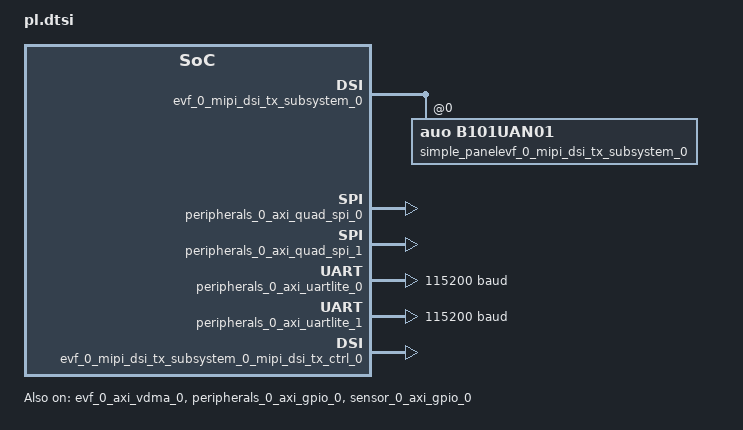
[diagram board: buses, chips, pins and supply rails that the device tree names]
/ {
	amba_pl: amba_pl {
		ranges;
		compatible = "simple-bus";
		#address-cells = <1>;
		#size-cells = <1>;
		evf_0_axi_vdma_0: axi_vdma@43000000 {
			xlnx,enable-debug-info-9 = <0x0>;
			xlnx,c-enable-mm2s-param-updt = <0>;
			xlnx,c-enable-s2mm-delay-counter = <1>;
			xlnx,dlytmr-resolution = <125>;
			xlnx,rable = <0>;
			xlnx,ip-name = "axi_vdma";
			xlnx,s2mm-genlock-num-masters = <1>;
			reg = <0x43000000 0x10000>;
			xlnx,use-mm2s-fsync = <0>;
			xlnx,s2mm-linebuffer-thresh = <4>;
			xlnx,c-use-s2mm-fsync = <2>;
			xlnx,c-enable-mm2s-buf-empty = <0>;
			xlnx,c-enable-s2mm-frm-counter = <1>;
			xlnx,c-enable-mm2s-delay-counter = <1>;
			xlnx,c-dlytmr-resolution = <125>;
			xlnx,c-enable-s2mm-buf-full = <0>;
			xlnx,dynamic-resolution = <1>;
			interrupt-names = "mm2s_introut";
			xlnx,s2mm-sof-enable = <0x1>;
			xlnx,mm2s-genlock-num-masters = <1>;
			xlnx,c-s2mm-genlock-num-masters = <1>;
			xlnx,c-enable-s2mm-fsync-out = <0>;
			xlnx,mm2s-linebuffer-thresh = <4>;
			xlnx,c-use-mm2s-fsync = <0>;
			xlnx,c-s2mm-linebuffer-thresh = <4>;
			xlnx,c-enable-mm2s-frm-counter = <1>;
			compatible = "xlnx,axi-vdma-6.3" , "xlnx,axi-vdma-1.00.a";
			xlnx,c-m-axis-mm2s-tdata-width = <96>;
			xlnx,c-enable-all = <0>;
			interrupt-parent = <&intc>;
			xlnx,s2mm-max-burst-length = <8>;
			xlnx,c-dynamic-resolution = <1>;
			xlnx,c-enable-s2mm-rst-out = <0>;
			xlnx,mm2s-sof-enable = <1>;
			xlnx,include-s2mm-dre = <0x0>;
			xlnx,c-s2mm-sof-enable = <1>;
			xlnx,c-enable-mm2s-fsync-out = <0>;
			xlnx,c-mm2s-genlock-num-masters = <1>;
			xlnx,c-mm2s-linebuffer-thresh = <4>;
			xlnx,c-enable-tstvec = <0>;
			xlnx,mm2s-max-burst-length = <256>;
			xlnx,c-s2mm-max-burst-length = <8>;
			status = "okay";
			xlnx,c-enable-mm2s-rst-out = <0>;
			xlnx,include-mm2s-dre = <0x0>;
			xlnx,c-include-s2mm-dre = <0>;
			xlnx,c-mm2s-sof-enable = <1>;
			xlnx,name = "evf_0_axi_vdma_0";
			xlnx,c-enable-s2mm-frmstr-reg = <0>;
			interrupts = < 0 33 4 >;
			xlnx,c-include-sg = <0>;
			xlnx,flush-on-fsync = <0x1>;
			xlnx,c-m-axi-s2mm-data-width = <64>;
			xlnx,c-enable-s2mm-sts-reg = <0>;
			xlnx,include-s2mm-sf = <1>;
			xlnx,c-mm2s-max-burst-length = <256>;
			xlnx,s2mm-linebuffer-depth = <0x200>;
			xlnx,include-s2mm = <0x0>;
			xlnx,c-include-mm2s-dre = <0>;
			clocks = <&clkc 15>, <&clkc 15>, <&clkc 15>;
			xlnx,c-enable-mm2s-frmstr-reg = <0>;
			xlnx,enable-debug-info-10 = <0>;
			xlnx,addrwidth = <0x20>;
			xlnx,enable-debug-info-11 = <0>;
			xlnx,enable-debug-info-12 = <0>;
			xlnx,edk-iptype = "PERIPHERAL";
			xlnx,c-flush-on-fsync = <1>;
			xlnx,c-m-axi-mm2s-data-width = <128>;
			xlnx,use-fsync = <1>;
			xlnx,s2mm-genlock-repeat-en = <1>;
			xlnx,enable-vert-flip = <0x0>;
			xlnx,enable-debug-info-13 = <0x0>;
			xlnx,include-mm2s-sf = <0>;
			xlnx,include-internal-genlock = <0x1>;
			xlnx,enable-debug-info-14 = <0x1>;
			xlnx,c-include-s2mm-sf = <1>;
			clock-names = "m_axi_mm2s_aclk" , "m_axis_mm2s_aclk" , "s_axi_lite_aclk";
			xlnx,enable-debug-info-15 = <0x1>;
			xlnx,mm2s-linebuffer-depth = <0x200>;
			xlnx,include-mm2s = <0x1>;
			xlnx,c-single-interface = <0>;
			xlnx,c-s2mm-linebuffer-depth = <512>;
			xlnx,c-addr-width = <32>;
			xlnx,c-include-s2mm = <0>;
			xlnx,s2mm-genlock-mode = <0x0>;
			xlnx,c-s-axis-s2mm-tdata-width = <32>;
			xlnx,flush-fsync = <0x1>;
			xlnx,select-xpm = <0>;
			xlnx,s2mm-data-width = <0x40>;
			xlnx,num-fstores = <0x1>;
			xlnx,enable-vidparam-reads = <0x1>;
			xlnx,mm2s-genlock-repeat-en = <0>;
			xlnx,c-use-fsync = <1>;
			xlnx,c-s2mm-genlock-repeat-en = <1>;
			xlnx,c-enable-vert-flip = <0>;
			xlnx,prmry-is-aclk-async = <0>;
			xlnx,c-include-internal-genlock = <1>;
			xlnx,c-include-mm2s-sf = <0>;
			xlnx,s2mm-tdata-width = <0x20>;
			xlnx,enable-vidprmtr-reads = <1>;
			xlnx,c-include-mm2s = <1>;
			xlnx,c-mm2s-linebuffer-depth = <512>;
			xlnx,mm2s-genlock-mode = <0x0>;
			xlnx,enable-debug-info-0 = <0>;
			xlnx,enable-debug-all = <0x0>;
			xlnx,c-s2mm-genlock-mode = <0>;
			xlnx,enable-debug-info-1 = <0x0>;
			xlnx,mm2s-data-width = <0x80>;
			xlnx,enable-debug-info-2 = <0>;
			xlnx,c-enable-s2mm-param-updt = <0>;
			xlnx,c-num-fstores = <1>;
			xlnx,enable-debug-info-3 = <0>;
			xlnx,enable-debug-info-4 = <0>;
			xlnx,c-mm2s-genlock-repeat-en = <0>;
			xlnx,enable-debug-info-5 = <0x0>;
			xlnx,c-prmry-is-aclk-async = <0>;
			xlnx,mm2s-tdata-width = <0x60>;
			xlnx,enable-debug-info-6 = <0x1>;
			xlnx,enable-debug-info-7 = <0x1>;
			xlnx,c-enable-vidprmtr-reads = <1>;
			xlnx,use-s2mm-fsync = <2>;
			xlnx,enable-debug-info-8 = <0>;
			xlnx,c-mm2s-genlock-mode = <0>;
			dma-channel@43000000 {
				interrupts = < 0 33 4 >;
				xlnx,datawidth = <0x60>;
				xlnx,device-id = <0x0>;
				compatible = "xlnx,axi-vdma-mm2s-channel";
			};
		};
		evf_0_mipi_dsi_tx_subsystem_0: mipi_dsi_tx_subsystem@43c00000 {
			xlnx,data-lane2-byte = "Same_Byte";
			xlnx,hp-io-bank-name = "64_(HP)";
			xlnx,dphy-lanes = <4>;
			xlnx,dsi-periodic-cntr-width = <32>;
			xlnx,rable = <0>;
			xlnx,ip-name = "mipi_dsi_tx_subsystem";
			reg = <0x43c00000 0x10000>;
			xlnx,dsi-byte-fifo = <2048>;
			xlnx,dsi-periodic-patrn-len = <4096>;
			xlnx,supportlevel = <1>;
			xlnx,clk-lane-io-loc-name = "None";
			xlnx,dsi-data-type = <0>;
			xlnx,include-dcs-cmd-mode;
			xlnx,clk-lane-io-loc = "None";
			interrupt-names = "interrupt";
			xlnx,dphy-hs-timeout = <65541>;
			compatible = "xlnx,mipi-dsi-tx-subsystem-2.3" , "xlnx,dsi";
			xlnx,is-7series;
			xlnx,idly-tap = <1>;
			xlnx,dsi-crc-gen;
			xlnx,dsi-num-lanes = <4>;
			xlnx,cmn-proj-family = <0>;
			interrupt-parent = <&intc>;
			xlnx,data-lane1-io-loc-name = "None";
			xlnx,dsi-init-deskew-patrn-len = <4096>;
			xlnx,data-lane3-io-loc-name = "None";
			xlnx,data-lane1-byte = "Same_Byte";
			xlnx,dphy-esc-timeout = <25600>;
			xlnx,dsi-datatype = "RGB888";
			xlnx,cal-mode = "NONE";
			status = "okay";
			xlnx,data-lane0-io-position = <2>;
			xlnx,data-lane2-io-position = <6>;
			xlnx,name = "evf_0_mipi_dsi_tx_subsystem_0";
			interrupts = < 0 34 4 >;
			xlnx,data-lane3-io-loc = "None";
			xlnx,dphy-linerate = <800>;
			xlnx,dsi-lanes = <4>;
			clocks = <&misc_clk_0>, <&clkc 15>;
			xlnx,mipi-slv-int = <0>;
			xlnx,data-lane2-io-loc = "None";
			xlnx,dsi-pixels-perbeat = <4>;
			xlnx,stretch-line-rate = <3200>;
			xlnx,data-lane3-byte = "Same_Byte";
			xlnx,dphy-esc-clk-period = <20>;
			xlnx,edk-iptype = "PERIPHERAL";
			clock-names = "dphy_clk_200M" , "s_axis_aclk";
			xlnx,ooc-vid-clk = <0x65b710>;
			xlnx,data-lane0-byte = "Same_Byte";
			xlnx,data-lane1-io-loc = "None";
			xlnx,hp-io-bank-selection = <64>;
			xlnx,dsi-pixels = <4>;
			xlnx,dphytx-board-interface = "Custom";
			xlnx,data-lane0-io-loc-name = "None";
			xlnx,dphy-preset = "None";
			xlnx,clk-lane-io-position = <0>;
			xlnx,data-lane0-io-loc = "None";
			xlnx,data-lane2-io-loc-name = "None";
			xlnx,hs-line-rate = <800>;
			xlnx,axis-tdata-width = <96>;
			xlnx,dphy-lpx-period = <50>;
			xlnx,data-lane1-io-position = <4>;
			xlnx,dphy-mode = "MASTER";
			xlnx,dsi-periodic-time = <50>;
			xlnx,data-lane3-io-position = <8>;
			simple_panelevf_0_mipi_dsi_tx_subsystem_0: simple_panel@0 {
				compatible = "auo,b101uan01";
				reg = <0>;
			};
			encoder_dsi_portevf_0_mipi_dsi_tx_subsystem_0: port@0 {
				reg = <0>;
			};
		};
		peripherals_0_axi_gpio_0: axi_gpio@41200000 {
			xlnx,gpio-board-interface = "Custom";
			compatible = "xlnx,axi-gpio-2.0" , "xlnx,xps-gpio-1.00.a";
			xlnx,all-outputs = <1>;
			xlnx,gpio-width = <23>;
			xlnx,rable = <0>;
			xlnx,dout-default = <0x00000000>;
			xlnx,is-dual = <1>;
			xlnx,ip-name = "axi_gpio";
			xlnx,tri-default-2 = <0xFFFFFFFF>;
			reg = <0x41200000 0x10000>;
			xlnx,all-inputs-2 = <1>;
			clocks = <&clkc 15>;
			xlnx,all-outputs-2 = <0>;
			xlnx,interrupt-present = <0>;
			xlnx,gpio2-board-interface = "Custom";
			xlnx,edk-iptype = "PERIPHERAL";
			xlnx,dout-default-2 = <0x00000000>;
			xlnx,gpio2-width = <8>;
			status = "okay";
			clock-names = "s_axi_aclk";
			xlnx,tri-default = <0xFFFFFFFF>;
			xlnx,name = "peripherals_0_axi_gpio_0";
			xlnx,all-inputs = <0>;
		};
		peripherals_0_axi_quad_spi_0: axi_quad_spi@41e00000 {
			xlnx,lsb-stup = <0>;
			num-cs = <0x1>;
			xlnx,master-mode = <1>;
			xlnx,multiples16 = <1>;
			xlnx,rable = <0>;
			fifo-size = <0>;
			xlnx,ip-name = "axi_quad_spi";
			reg = <0x41e00000 0x10000>;
			bits-per-word = <8>;
			xlnx,spi-memory = <1>;
			xlnx,type-of-axi4-interface = <0>;
			xlnx,use-startup-int = <0>;
			xlnx,slaveonly = <0>;
			xlnx,spi-mode = <0>;
			interrupt-names = "ip2intc_irpt";
			compatible = "xlnx,axi-quad-spi-3.2" , "xlnx,xps-spi-2.00.a";
			xlnx,byte-level-interrupt-en = <0>;
			xlnx,s-axi4-addr-width = <24>;
			xlnx,sck-ratio = <4>;
			interrupt-parent = <&intc>;
			xlnx,async-clk = <1>;
			status = "okay";
			xlnx,sck-ratio1 = <1>;
			xlnx,fifo-included = <0>;
			xlnx,name = "peripherals_0_axi_quad_spi_0";
			interrupts = < 0 31 1 >;
			xlnx,use-startup-ext = <0>;
			xlnx,hasfifos = <0>;
			xlnx,s-axi4-id-width = <4>;
			xlnx,shared-startup = <0>;
			xlnx,new-seq-en = <1>;
			xlnx,qspi-board-interface = "Custom";
			clocks = <&misc_clk_1>, <&clkc 15>;
			xlnx,edk-iptype = "PERIPHERAL";
			xlnx,fifo-depth = <0>;
			clock-names = "ext_spi_clk" , "s_axi_aclk";
			xlnx,axi-interface = <0>;
			xlnx,num-ss-bits = <0x1>;
			xlnx,select-xpm = <0>;
			xlnx,xip-mode = <0>;
			xlnx,xip-perf-mode = <1>;
			xlnx,dual-quad-mode = <0>;
			xlnx,num-transfer-bits = <8>;
			xlnx,s-axi4-data-width = <32>;
			xlnx,use-startup = <0>;
			xlnx,spi-mem-addr-bits = <24>;
			xlnx,uc-family = <0>;
			xlnx,Axi4-address = <0>;
			xlnx,sub-family = "zynq";
		};
		peripherals_0_axi_quad_spi_1: axi_quad_spi@41e10000 {
			xlnx,lsb-stup = <0>;
			num-cs = <0x1>;
			xlnx,master-mode = <1>;
			xlnx,multiples16 = <1>;
			xlnx,rable = <0>;
			fifo-size = <0>;
			xlnx,ip-name = "axi_quad_spi";
			reg = <0x41e10000 0x10000>;
			bits-per-word = <8>;
			xlnx,spi-memory = <1>;
			xlnx,type-of-axi4-interface = <0>;
			xlnx,use-startup-int = <0>;
			xlnx,slaveonly = <0>;
			xlnx,spi-mode = <0>;
			interrupt-names = "ip2intc_irpt";
			compatible = "xlnx,axi-quad-spi-3.2" , "xlnx,xps-spi-2.00.a";
			xlnx,byte-level-interrupt-en = <0>;
			xlnx,s-axi4-addr-width = <24>;
			xlnx,sck-ratio = <2>;
			interrupt-parent = <&intc>;
			xlnx,async-clk = <1>;
			status = "okay";
			xlnx,sck-ratio1 = <1>;
			xlnx,fifo-included = <0>;
			xlnx,name = "peripherals_0_axi_quad_spi_1";
			interrupts = < 0 32 1 >;
			xlnx,use-startup-ext = <0>;
			xlnx,hasfifos = <0>;
			xlnx,s-axi4-id-width = <4>;
			xlnx,shared-startup = <0>;
			xlnx,new-seq-en = <1>;
			xlnx,qspi-board-interface = "Custom";
			clocks = <&misc_clk_1>, <&clkc 15>;
			xlnx,edk-iptype = "PERIPHERAL";
			xlnx,fifo-depth = <0>;
			clock-names = "ext_spi_clk" , "s_axi_aclk";
			xlnx,axi-interface = <0>;
			xlnx,num-ss-bits = <0x1>;
			xlnx,select-xpm = <0>;
			xlnx,xip-mode = <0>;
			xlnx,xip-perf-mode = <1>;
			xlnx,dual-quad-mode = <0>;
			xlnx,num-transfer-bits = <8>;
			xlnx,s-axi4-data-width = <32>;
			xlnx,use-startup = <0>;
			xlnx,spi-mem-addr-bits = <24>;
			xlnx,uc-family = <0>;
			xlnx,Axi4-address = <0>;
			xlnx,sub-family = "zynq";
		};
		misc_clk_1: misc_clk_1 {
			compatible = "fixed-clock";
			clock-frequency = <10000000>;
			#clock-cells = <0>;
		};
		peripherals_0_axi_uartlite_0: axi_uartlite@42c00000 {
			interrupts = < 0 29 1 >;
			compatible = "xlnx,axi-uartlite-2.0" , "xlnx,xps-uartlite-1.00.a";
			xlnx,uartlite-board-interface = "Custom";
			xlnx,s-axi-aclk-freq-hz-d = <100>;
			interrupt-parent = <&intc>;
			xlnx,rable = <0>;
			xlnx,ip-name = "axi_uartlite";
			reg = <0x42c00000 0x10000>;
			xlnx,baudrate = <115200>;
			clocks = <&clkc 15>;
			current-speed = <115200>;
			xlnx,use-parity = <0>;
			xlnx,edk-iptype = "PERIPHERAL";
			xlnx,odd-parity = <0>;
			status = "okay";
			clock-names = "s_axi_aclk";
			interrupt-names = "interrupt";
			xlnx,name = "peripherals_0_axi_uartlite_0";
			xlnx,data-bits = <8>;
			xlnx,parity = "No_Parity";
		};
		peripherals_0_axi_uartlite_1: axi_uartlite@42c10000 {
			interrupts = < 0 30 1 >;
			compatible = "xlnx,axi-uartlite-2.0" , "xlnx,xps-uartlite-1.00.a";
			xlnx,uartlite-board-interface = "Custom";
			xlnx,s-axi-aclk-freq-hz-d = <100>;
			interrupt-parent = <&intc>;
			xlnx,rable = <0>;
			xlnx,ip-name = "axi_uartlite";
			reg = <0x42c10000 0x10000>;
			xlnx,baudrate = <115200>;
			clocks = <&clkc 15>;
			current-speed = <115200>;
			xlnx,use-parity = <0>;
			xlnx,edk-iptype = "PERIPHERAL";
			xlnx,odd-parity = <0>;
			status = "okay";
			clock-names = "s_axi_aclk";
			interrupt-names = "interrupt";
			xlnx,name = "peripherals_0_axi_uartlite_1";
			xlnx,data-bits = <8>;
			xlnx,parity = "No_Parity";
		};
		sensor_0_axi_gpio_0: axi_gpio@41210000 {
			xlnx,gpio-board-interface = "Custom";
			compatible = "xlnx,axi-gpio-2.0" , "xlnx,xps-gpio-1.00.a";
			xlnx,all-outputs = <1>;
			xlnx,gpio-width = <14>;
			xlnx,rable = <0>;
			xlnx,dout-default = <0x00000000>;
			xlnx,is-dual = <1>;
			xlnx,ip-name = "axi_gpio";
			xlnx,tri-default-2 = <0xFFFFFFFF>;
			reg = <0x41210000 0x10000>;
			xlnx,all-inputs-2 = <1>;
			clocks = <&clkc 15>;
			xlnx,all-outputs-2 = <0>;
			xlnx,interrupt-present = <0>;
			xlnx,gpio2-board-interface = "Custom";
			xlnx,edk-iptype = "PERIPHERAL";
			xlnx,dout-default-2 = <0x00000000>;
			xlnx,gpio2-width = <3>;
			status = "okay";
			clock-names = "s_axi_aclk";
			xlnx,tri-default = <0xFFFFFFFF>;
			xlnx,name = "sensor_0_axi_gpio_0";
			xlnx,all-inputs = <0>;
		};
		evf_0_mipi_dsi_tx_subsystem_0_mipi_dsi_tx_ctrl_0: mipi_dsi_tx_ctrl@0 {
			xlnx,dsi-pixels = <4>;
			compatible = "xlnx,mipi-dsi-tx-ctrl-1.0";
			xlnx,axis-tuser-width = <1>;
			xlnx,dsi-xmit-periodic-deskew = <0>;
			xlnx,dsi-crc-gen = <1>;
			xlnx,dsi-xmit-alt-deskew = <0>;
			xlnx,dsi-periodic-cntr-width = <32>;
			xlnx,rable = <0>;
			xlnx,dsi-1pxl-wdth = <24>;
			xlnx,dsi-init-deskew-patrn-len = <4096>;
			xlnx,ip-name = "mipi_dsi_tx_ctrl";
			xlnx,dsi-2pxl-wdth = <48>;
			xlnx,dsi-lanes = <4>;
			reg = <0x00000000 0x10000>;
			xlnx,dsi-3pxl-wdth = <72>;
			clocks = <&misc_clk_2>, <&misc_clk_0>, <&misc_clk_2>, <&misc_clk_2>;
			xlnx,mipi-slv-int = <0>;
			xlnx,line-rate = <800>;
			xlnx,dsi-datatype = <0x3E>;
			xlnx,dsi-4pxl-wdth = <96>;
			xlnx,dsi-periodic-patrn-len = <4096>;
			xlnx,dsi-byte-fifo = <2048>;
			xlnx,dsi-act-pxl-wdth = <96>;
			xlnx,edk-iptype = "PERIPHERAL";
			xlnx,axis-tdata-width = <96>;
			xlnx,dsi-xmit-initial-deskew = <0>;
			status = "okay";
			clock-names = "core_clk" , "s_axis_aclk" , "stream_clk" , "txbyteclkhs";
			xlnx,include-cmd-mode = <1>;
			xlnx,dsi-periodic-time = <50>;
			xlnx,name = "evf_0_mipi_dsi_tx_subsystem_0_mipi_dsi_tx_ctrl_0";
		};
		misc_clk_0: misc_clk_0 {
			compatible = "fixed-clock";
			clock-frequency = <200000000>;
			#clock-cells = <0>;
		};
		misc_clk_2: misc_clk_2 {
			compatible = "fixed-clock";
			clock-frequency = <100000000>;
			#clock-cells = <0>;
		};
	};
};
